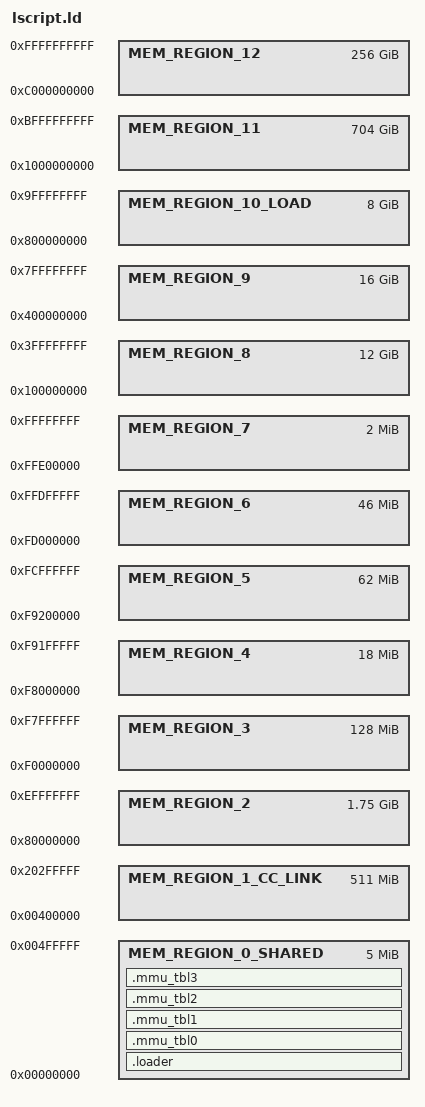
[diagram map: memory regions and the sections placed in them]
/*
 * Automatically generated by AutoMetalBench
 * Please make sure to define the attributes especified for each descriptor
 */

MEMORY
{
	MEM_REGION_0_SHARED :	 ORIGIN = 0x0, LENGTH = 0x500000
	MEM_REGION_1_CC_LINK :	 ORIGIN = 0x400000, LENGTH = 0x1ff00000
	MEM_REGION_2 :	 ORIGIN = 0x80000000, LENGTH = 0x70000000
	MEM_REGION_3 :	 ORIGIN = 0xf0000000, LENGTH = 0x8000000
	MEM_REGION_4 :	 ORIGIN = 0xf8000000, LENGTH = 0x1200000
	MEM_REGION_5 :	 ORIGIN = 0xf9200000, LENGTH = 0x3e00000
	MEM_REGION_6 :	 ORIGIN = 0xfd000000, LENGTH = 0x2e00000
	MEM_REGION_7 :	 ORIGIN = 0xffe00000, LENGTH = 0x200000
	MEM_REGION_8 :	 ORIGIN = 0x100000000, LENGTH = 0x300000000
	MEM_REGION_9 :	 ORIGIN = 0x400000000, LENGTH = 0x400000000
	MEM_REGION_10_LOAD :	 ORIGIN = 0x800000000, LENGTH = 0x200000000
	MEM_REGION_11 :	 ORIGIN = 0x1000000000, LENGTH = 0xb000000000
	MEM_REGION_12 :	 ORIGIN = 0xc000000000, LENGTH = 0x4000000000
}

SECTIONS
{
.loader : {
	. = ALIGN(64);
	__loader_start = .;
	*(.loader)
	*(.loader.*)
	__loader_end = .;
} > MEM_REGION_0_SHARED
.mmu_tbl0 : {
	. = ALIGN(64);
	__mmu_tbl0_start = .;
	KEEP(*(.mmu_tbl0))
	__mmu_tbl0_end = .;
} > MEM_REGION_0_SHARED
.mmu_tbl1 : {
	. = ALIGN(4096);
	__mmu_tbl1_start = .;
	KEEP(*(.mmu_tbl1))
	__mmu_tbl1_end = .;
} > MEM_REGION_0_SHARED
.mmu_tbl2 : {
	. = ALIGN(4096);
	__mmu_tbl2_start = .;
	KEEP(*(.mmu_tbl2))
	__mmu_tbl2_end = .;
} > MEM_REGION_0_SHARED
.mmu_tbl3 : {
	. = ALIGN(4096);
	__mmu_tbl3_start = .;
	KEEP(*(.mmu_tbl3))
	__mmu_tbl3_end = .;
} > MEM_REGION_0_SHARED
}
